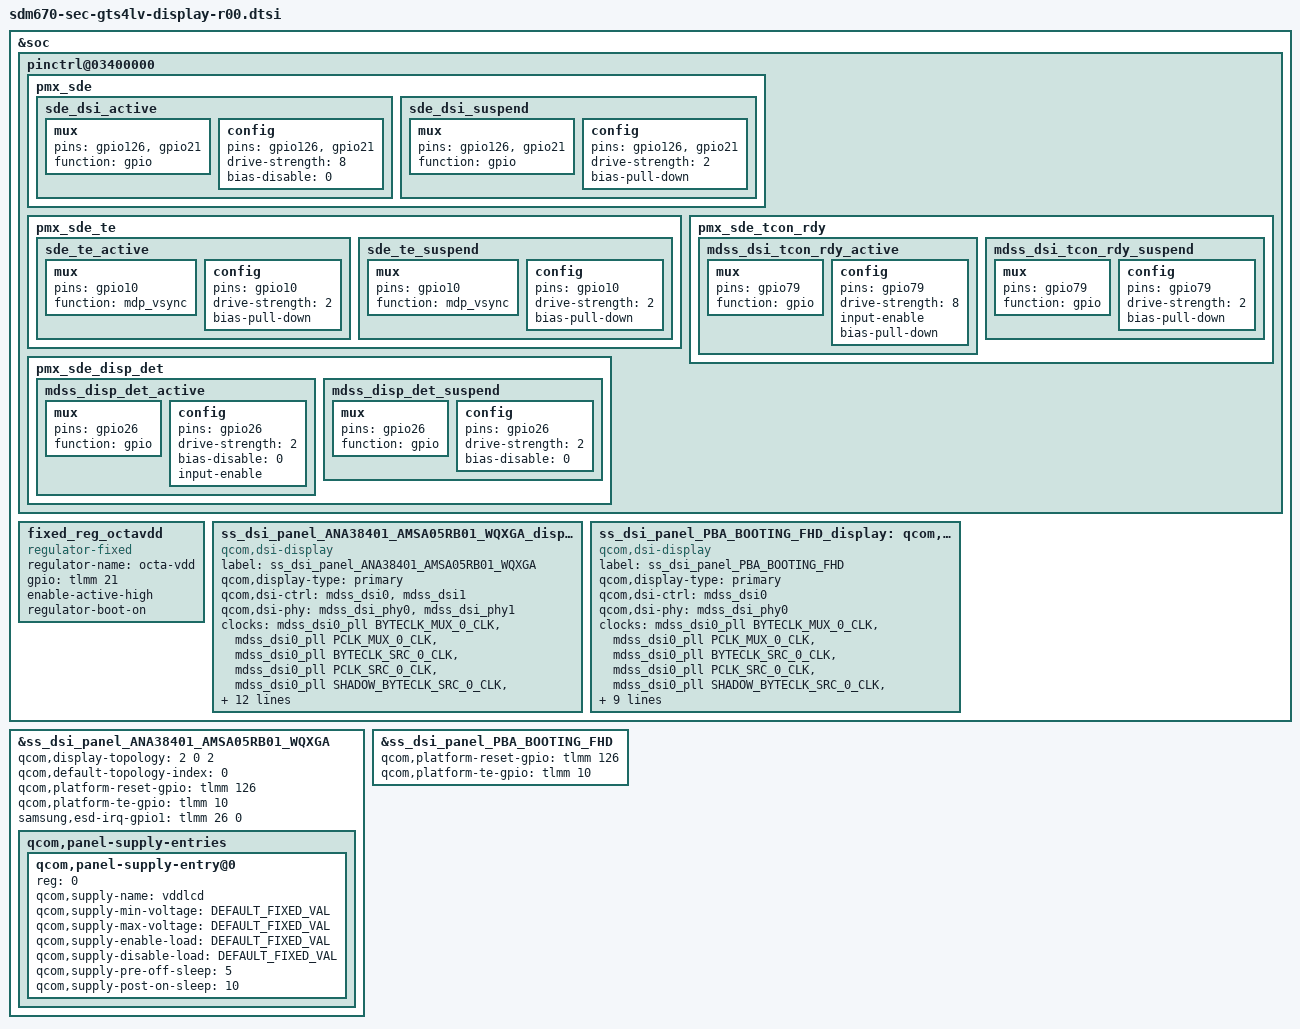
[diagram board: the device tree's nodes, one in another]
/* Copyright (c) 2016-2017, The Linux Foundation. All rights reserved.
 *
 * This program is free software; you can redistribute it and/or modify
 * it under the terms of the GNU General Public License version 2 and
 * only version 2 as published by the Free Software Foundation.
 *
 * This program is distributed in the hope that it will be useful,
 * but WITHOUT ANY WARRANTY; without even the implied warranty of
 * MERCHANTABILITY or FITNESS FOR A PARTICULAR PURPOSE.  See the
 * GNU General Public License for more details.
 */
#include "../../../../drivers/gpu/drm/msm/samsung/ANA38401_AMSA05RB01/dsi_panel_ANA38401_AMSA05RB01_wqxga_octa_cmd.dtsi"
#include "../../../../drivers/gpu/drm/msm/samsung/PBA_BOOTING/dsi_panel_PBA_BOOTING_fhd_video.dtsi"

#define DEFAULT_FIXED_VAL	0

&soc {
	pinctrl@03400000 {
		pmx_sde: pmx_sde {
			sde_dsi_active: sde_dsi_active {
				mux {
					pins = "gpio126", "gpio21";
					function = "gpio";
				};

				config {
					pins = "gpio126",  "gpio21";
					drive-strength = <8>;   /* 8 mA */
					bias-disable = <0>;   /* no pull */
				};
			};
			sde_dsi_suspend: sde_dsi_suspend {
				mux {
					pins = "gpio126",  "gpio21";
					function = "gpio";
				};

				config {
					pins = "gpio126",  "gpio21";
					drive-strength = <2>;   /* 2 mA */
					bias-pull-down;         /* PULL DOWN */
				};
			};
		};

		pmx_sde_te {
			sde_te_active: sde_te_active {
				mux {
					pins = "gpio10";
					function = "mdp_vsync";
				};

				config {
					pins = "gpio10";
					drive-strength = <2>;   /* 2 mA */
					bias-pull-down;         /* PULL DOWN */
				};
			};

			sde_te_suspend: sde_te_suspend {
				mux {
					pins = "gpio10";
					function = "mdp_vsync";
				};

				config {
					pins = "gpio10";
					drive-strength = <2>;   /* 2 mA */
					bias-pull-down;         /* PULL DOWN */
				};
			};
		};
		pmx_sde_tcon_rdy {
			mdss_dsi_tcon_rdy_active: mdss_dsi_tcon_rdy_active {
				mux {
					pins = "gpio79";
					function = "gpio";
				};

				config {
					pins = "gpio79";
					drive-strength = <8>; /* 8 mA */
					input-enable;
					bias-pull-down;
				};
			};
			mdss_dsi_tcon_rdy_suspend: mdss_dsi_tcon_rdy_suspend {
				mux {
					pins = "gpio79";
					function = "gpio";
				};

				config {
					pins = "gpio79";
					drive-strength = <2>; /* 2 mA */
					bias-pull-down; /* pull down */
				};
			};
		};
		pmx_sde_disp_det {
			mdss_disp_det_active: mdss_disp_det_active {
				mux {
					pins = "gpio26";
					function = "gpio";
				};
				config {
					pins = "gpio26";
					drive-strength = <2>; /* 8 mA */
					bias-disable = <0>; /* no pull */
					input-enable;
				};
			};

			mdss_disp_det_suspend: mdss_disp_det_suspend {
				mux {
					pins = "gpio26";
					function = "gpio";
				};
				config {
					pins = "gpio26";
					drive-strength = <2>; /* 2 mA */
					bias-disable = <0>; /* no pull */
				};
			};
		};
	};
};

&soc {
	fixed_reg_octavdd: fixed_reg_octavdd {
		compatible = "regulator-fixed";
		status = "okay";
		regulator-name = "octa-vdd";
		gpio = <&tlmm 21 0>; /* LCD_LDO_EN */
		enable-active-high;
		regulator-boot-on;
	};
};

&soc {
	ss_dsi_panel_ANA38401_AMSA05RB01_WQXGA_display: qcom,dsi-display@0 {
		compatible = "qcom,dsi-display";
		label = "ss_dsi_panel_ANA38401_AMSA05RB01_WQXGA";
		qcom,display-type = "primary";

		qcom,dsi-ctrl = <&mdss_dsi0 &mdss_dsi1>;
		qcom,dsi-phy = <&mdss_dsi_phy0 &mdss_dsi_phy1>;

		clocks = <&mdss_dsi0_pll BYTECLK_MUX_0_CLK>,
			<&mdss_dsi0_pll PCLK_MUX_0_CLK>,
			<&mdss_dsi0_pll BYTECLK_SRC_0_CLK>,
			<&mdss_dsi0_pll PCLK_SRC_0_CLK>,
			<&mdss_dsi0_pll SHADOW_BYTECLK_SRC_0_CLK>,
			<&mdss_dsi0_pll SHADOW_PCLK_SRC_0_CLK>;
		clock-names = "mux_byte_clk", "mux_pixel_clk",
				"src_byte_clk", "src_pixel_clk",
				"shadow_byte_clk", "shadow_pixel_clk";

		pinctrl-names = "panel_active", "panel_suspend";
		pinctrl-0 = <&sde_dsi_active &sde_te_active &mdss_dsi_tcon_rdy_active &mdss_disp_det_active>;
		pinctrl-1 = <&sde_dsi_suspend &sde_te_suspend &mdss_dsi_tcon_rdy_suspend &mdss_disp_det_suspend>;
		qcom,platform-te-gpio = <&tlmm 10 0>;
		qcom,platform-reset-gpio = <&tlmm 126 0>;

		qcom,dsi-panel = <&ss_dsi_panel_ANA38401_AMSA05RB01_WQXGA>;
		vddlcd-supply = <&fixed_reg_octavdd>;
	};

	/* PBA */
	ss_dsi_panel_PBA_BOOTING_FHD_display: qcom,dsi-display@1 {
		compatible = "qcom,dsi-display";
		label = "ss_dsi_panel_PBA_BOOTING_FHD";
		qcom,display-type = "primary";

		qcom,dsi-ctrl = <&mdss_dsi0>;
		qcom,dsi-phy = <&mdss_dsi_phy0>;

		clocks = <&mdss_dsi0_pll BYTECLK_MUX_0_CLK>,
			<&mdss_dsi0_pll PCLK_MUX_0_CLK>,
			<&mdss_dsi0_pll BYTECLK_SRC_0_CLK>,
			<&mdss_dsi0_pll PCLK_SRC_0_CLK>,
			<&mdss_dsi0_pll SHADOW_BYTECLK_SRC_0_CLK>,
			<&mdss_dsi0_pll SHADOW_PCLK_SRC_0_CLK>;
		clock-names = "mux_byte_clk", "mux_pixel_clk",
				"src_byte_clk", "src_pixel_clk",
				"shadow_byte_clk", "shadow_pixel_clk";

		pinctrl-names = "panel_active", "panel_suspend";
		pinctrl-0 = <&sde_dsi_active &sde_te_active &mdss_dsi_tcon_rdy_active &mdss_disp_det_active>;
		pinctrl-1 = <&sde_dsi_suspend &sde_te_suspend &mdss_dsi_tcon_rdy_suspend &mdss_disp_det_suspend>;
		qcom,platform-te-gpio = <&tlmm 10 0>;

		qcom,dsi-panel = <&ss_dsi_panel_PBA_BOOTING_FHD>;
	};
};

&ss_dsi_panel_ANA38401_AMSA05RB01_WQXGA {
	qcom,display-topology = <2 0 2>;
	qcom,default-topology-index = <0>;

	qcom,platform-reset-gpio = <&tlmm 126 0>;
	qcom,platform-te-gpio = <&tlmm 10 0>;
	/delete-property/ qcom,panel-mode-gpio;
	samsung,esd-irq-gpio1 = <&tlmm 26 0>; /* DISP_DET */

	qcom,panel-supply-entries {
		#address-cells = <1>;
		#size-cells = <0>;

		/* use fixed regulator instead of samsung,panel-extra-power-gpio
		 * or qcom,platform-enable-gpio. */
		/* VDD 3.3V */
		qcom,panel-supply-entry@0 {
			reg = <0>;
			qcom,supply-name = "vddlcd";
			qcom,supply-min-voltage = <DEFAULT_FIXED_VAL>;
			qcom,supply-max-voltage = <DEFAULT_FIXED_VAL>;
			qcom,supply-enable-load = <DEFAULT_FIXED_VAL>;
			qcom,supply-disable-load = <DEFAULT_FIXED_VAL>;
			qcom,supply-pre-off-sleep = <5>;
			qcom,supply-post-on-sleep = <10>;
		};
	};
};

&ss_dsi_panel_PBA_BOOTING_FHD {
	qcom,platform-reset-gpio = <&tlmm 126 0>;
	qcom,platform-te-gpio = <&tlmm 10 0>;
};
